# N575F145_v1 register map
File version: 1.0
Registers are 32-bit, read-write, reset 0x0 unless marked. A register's access mark holds for its fields unless they carry their own. Offsets are from the block's base; [hi:lo] are bit positions; lines under a group give offsets from that group; {n}, {i} and the like mark numbered series.

## SCS — SCS Register Map
Base 0xE000E000
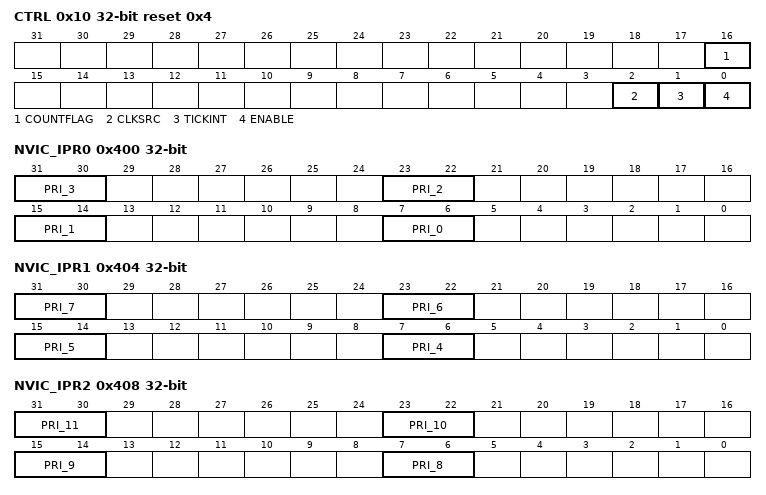
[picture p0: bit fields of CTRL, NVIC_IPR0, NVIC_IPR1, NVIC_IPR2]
0x10 CTRL reset 0x4 — SysTick Control and Status Register
  [16] COUNTFLAG — Count Flag. Returns 1 if timer counted to 0 since last time this register was read.
    0=Cleared on read or by a write to the Current Value register; 1=Set by a count transition from 1 to 0
  [2] CLKSRC — Clock Source
    0=Core clock unused; 1=Core clock used for SysTick, this bit will read as 1 and ignore writes
  [1] TICKINT — Enables SysTick Exception Request
    0=Counting down to 0 does not cause the SysTick exception to be pended. Software can use COUNTFLAG to determine if a count to zero has occurred; 1=Counting down to 0 will cause SysTick exception to be pended. Clearing the SysTick Current Value register by a register write in software will not cause SysTick to be pended
  [0] ENABLE
    0=The counter is disabled; 1=The counter will operate in a multi-shot manner
0x14 LOAD reset not defined — SysTick Reload value Register
  [23:0] RELOAD — SysTick Reload. Value to load into the Current Value register when the counter reaches 0. To generate a multi-shot timer with a period of N processor clock cycles, use a RELOAD value of N-1. For example, if the SysTick interrupt is required every 200 clock pulses, set RELOAD to 199.
0x18 VAL reset not defined — SysTick Current value Register
  [23:0] CURRENT — Current Counter Value. This is the value of the counter at the time it is sampled. The counter does not provide read-modify-write protection. The register is write-clear. A software write of any value will clear the register to 0 and also clear the COUNTFLAG bit.
0x100 NVIC_ISER — IRQ0 ~ IRQ31 Set-Enable Control Register
  [31:0] SETENA — Set-Enable Control. Enable one or more interrupts within a group of 32. Each bit represents an interrupt number from IRQ0 ~ IRQ31 (Vector number from 16 ~ 47). Writing 1 will enable the associated interrupt. Writing 0 has no effect. The register reads back the current enable state.
0x180 NVIC_ICER — IRQ0 ~ IRQ31 Clear-Enable Control Register
  [31:0] CLRENA — Clear-Enable Control. Disable one or more interrupts within a group of 32. Each bit represents an interrupt number from IRQ0 ~ IRQ31 (Vector number from 16 ~ 47). Writing 1 will disable the associated interrupt. Writing 0 has no effect. The register reads back with the current enable state.
0x200 NVIC_ISPR — IRQ0 ~ IRQ31 Set-Pending Control Register
  [31:0] SETPEND — Set-Pending Control. Writing 1 to a bit forces pending state of the associated interrupt under software control. Each bit represents an interrupt number from IRQ0 ~ IRQ31 (Vector number from 16 ~ 47). Writing 0 has no effect. The register reads back with the current pending state.
0x280 NVIC_ICPR — IRQ0 ~ IRQ31 Clear-Pending Control Register
  [31:0] CLRPEND — Clear-Pending Control. Writing 1 to a bit to clear the pending state of associated interrupt under software control. Each bit represents an interrupt number from IRQ0 ~ IRQ31 (Vector number from 16 ~ 47). Writing 0 has no effect. The register reads back with the current pending state.
0x400 NVIC_IPR0 — IRQ0 ~ IRQ3 Priority Control Register
  [8n+7:8n+6] PRI_{n} (n=0..3) — Priority of IRQ{n} "0" denotes the highest priority and "3" denotes lowest priority
0x404 NVIC_IPR1 — IRQ4 ~ IRQ7 Priority Control Register
  [8n-25:8n-26] PRI_{n} (n=4..7) — Priority of IRQ{n} "0" denotes the highest priority and "3" denotes lowest priority
0x408 NVIC_IPR2 — IRQ8 ~ IRQ11 Priority Control Register
  [8n-57:8n-58] PRI_{n} (n=8..11) — Priority of IRQ{n} "0" denotes the highest priority and "3" denotes lowest priority
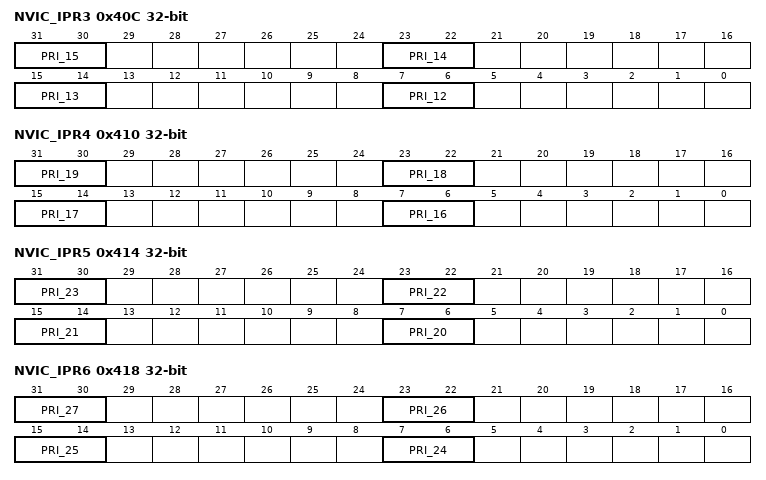
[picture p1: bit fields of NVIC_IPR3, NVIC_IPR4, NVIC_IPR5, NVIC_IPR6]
0x40C NVIC_IPR3 — IRQ12 ~ IRQ15 Priority Control Register
  [8n-89:8n-90] PRI_{n} (n=12..15) — Priority of IRQ{n} "0" denotes the highest priority and "3" denotes lowest priority
0x410 NVIC_IPR4 — IRQ16 ~ IRQ19 Priority Control Register
  [8n-121:8n-122] PRI_{n} (n=16..19) — Priority of IRQ{n} "0" denotes the highest priority and "3" denotes lowest priority
0x414 NVIC_IPR5 — IRQ20 ~ IRQ23 Priority Control Register
  [8n-153:8n-154] PRI_{n} (n=20..23) — Priority of IRQ{n} "0" denotes the highest priority and "3" denotes lowest priority
0x418 NVIC_IPR6 — IRQ24 ~ IRQ27 Priority Control Register
  [8n-185:8n-186] PRI_{n} (n=24..27) — Priority of IRQ{n} "0" denotes the highest priority and "3" denotes lowest priority
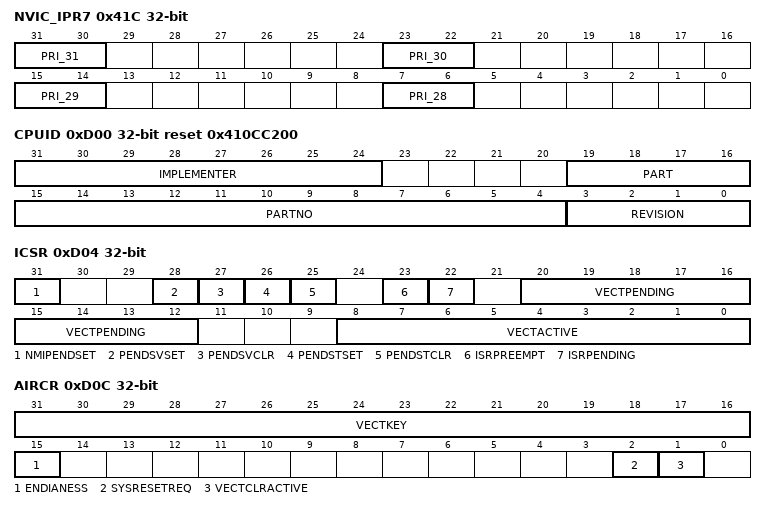
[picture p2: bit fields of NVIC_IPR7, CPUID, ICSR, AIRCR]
0x41C NVIC_IPR7 — IRQ28 ~ IRQ31 Priority Control Register
  [8n-217:8n-218] PRI_{n} (n=28..31) — Priority of IRQ{n} "0" denotes the highest priority and "3" denotes lowest priority
0xD00 CPUID ro reset 0x410CC200 — CPUID Base Register
  [31:24] IMPLEMENTER — Implementer Code Assigned By ARM. ARM = 0x41.
  [19:16] PART — ARMv6-M Parts. Reads as 0xC for ARMv6-M parts
  [15:4] PARTNO — Part Number. Reads as 0xC20.
  [3:0] REVISION — Revision. Reads as 0x0
0xD04 ICSR — Interrupt Control State Register
  [31] NMIPENDSET — NMI Pending Set Control. Setting this bit will activate an NMI. Since NMI is the highest priority exception, it will activate as soon as it is registered. Reads back with current state (1 if Pending, 0 if not).
  [28] PENDSVSET — Set A Pending PendSV Interrupt. This is normally used to request a context switch. Reads back with current state (1 if Pending, 0 if not).
  [27] PENDSVCLR — Clear A Pending PendSV Interrupt. Write 1 to clear a pending PendSV interrupt.
  [26] PENDSTSET — Set A pending SysTick. Reads back with current state (1 if Pending, 0 if not).
  [25] PENDSTCLR — Clear A pending SysTick. Write 1 to clear a pending SysTick.
  [23] ISRPREEMPT — ISR Preemptive. If set, a pending exception will be serviced on exit from the debug halt state.
  [22] ISRPENDING — ISR Pending. Indicates if an external configurable (NVIC generated) interrupt is pending.
  [20:12] VECTPENDING — Vector Pending. Indicates the exception number for the highest priority pending exception. The pending state includes the effect of memory-mapped enable and mask registers. It does not include the PRIMASK special-purpose register qualifier. A value of zero indicates no pending exceptions.
  [8:0] VECTACTIVE — Vector Active. 0: Thread mode. Value > 1: the exception number for the current executing exception.
0xD0C AIRCR — Application Interrupt and Reset Control Register
  [31:16] VECTKEY — Vector Key. The value 0x05FA must be written to this register, otherwise a write to register is UNPREDICTABLE.
  [15] ENDIANESS — Endianess. Read Only. Reads 0 indicating little endian machine.
  [2] SYSRESETREQ — System Reset Request. Writing 1 to this bit asserts a signal to request a reset by the external system.
    0=do not request a reset; 1=request reset
  [1] VECTCLRACTIVE — Clear All Active Vector. Clears all active state information for fixed and configurable exceptions. The effect of writing a 1 to this bit if the processor is not halted in Debug, is UNPREDICTABLE.
    0=do not clear state information; 1=clear state information
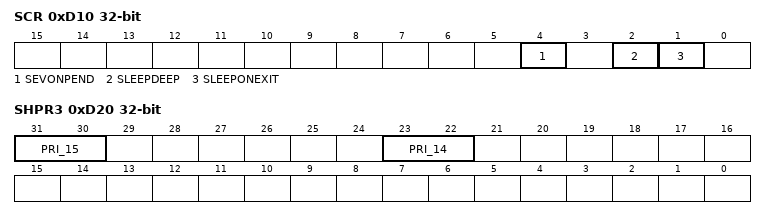
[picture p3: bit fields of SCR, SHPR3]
0xD10 SCR — System Control Register
  [4] SEVONPEND — Send Event On Pending Bit. When enabled, interrupt transitions from Inactive to Pending are included in the list of wakeup events for the WFE instruction. When an event or interrupt enters pending state, the event signal wakes up the processor from WFE. If the processor is not waiting for an event, the event is registered and affects the next WFE. The processor also wakes up on execution of an SEV instruction.
    0=only enabled interrupts or events can wake-up the processor, disabled interrupts are excluded; 1=enabled events and all interrupts, including disabled interrupts, can wake-up the processor
  [2] SLEEPDEEP — Sleep Deep Control. Controls whether the processor uses sleep or deep sleep as its low power mode: The SLEEPDEEP flag is also used in conjunction with PWRCON register to enter deeper power-down states than purely core sleep states.
    0=sleep; 1=deep sleep
  [1] SLEEPONEXIT — Sleep On Exception. When set to 1, the core can enter a sleep state on an exception return to Thread mode. This is the mode and exception level entered at reset, the base level of execution. Setting this bit to 1 enables an interrupt driven application to avoid returning to an empty main application.
0xD1C SHPR2 — System Handler Priority Register 2
  [31:30] PRI_11 — Priority Of System Handler 11 - SVCall "0" denotes the highest priority and "3" denotes lowest priority
0xD20 SHPR3 — System Handler Priority Register 3
  [31:30] PRI_15 — Priority Of System Handler 15 - SysTick "0" denotes the highest priority and "3" denotes lowest priority
  [23:22] PRI_14 — Priority Of System Handler 14 - PendSV "0" denotes the highest priority and "3" denotes lowest priority
